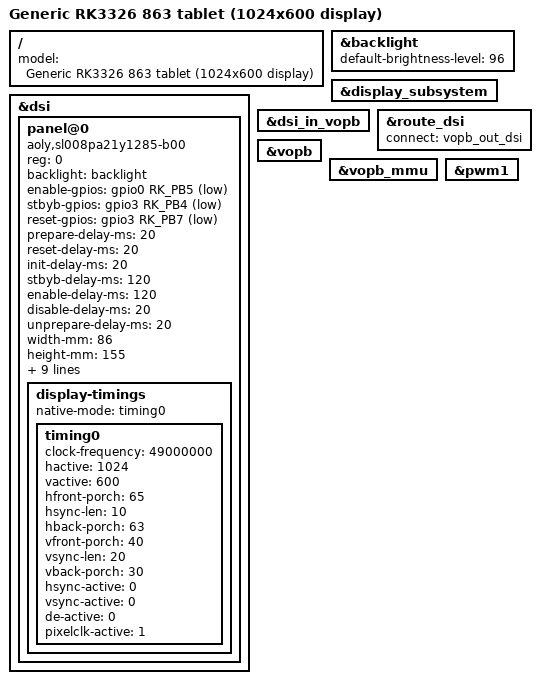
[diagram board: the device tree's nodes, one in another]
// SPDX-License-Identifier: (GPL-2.0+ OR MIT)

/dts-v1/;

#include <dt-bindings/display/drm_mipi_dsi.h>
#include "rk3326-863-tablet-common.dtsi"

/ {
	model = "Generic RK3326 863 tablet (1024x600 display)";
};

&backlight {
	default-brightness-level = <96>;
	status = "okay";
};

&display_subsystem {
	status = "okay";
};

&dsi {
	status = "okay";

	panel@0 {
		compatible = "aoly,sl008pa21y1285-b00",
			     "simple-panel-dsi";
		reg = <0>;
		status = "okay";
		backlight = <&backlight>;
		enable-gpios = <&gpio0 RK_PB5 GPIO_ACTIVE_LOW>;

		/*
		 * Preserved from the original DTB. Public Rockchip 6.1
		 * panel-simple does not currently consume this property.
		 */
		stbyb-gpios = <&gpio3 RK_PB4 GPIO_ACTIVE_LOW>;
		reset-gpios = <&gpio3 RK_PB7 GPIO_ACTIVE_LOW>;

		prepare-delay-ms = <20>;
		reset-delay-ms = <20>;
		init-delay-ms = <20>;
		stbyb-delay-ms = <120>;
		enable-delay-ms = <120>;
		disable-delay-ms = <20>;
		unprepare-delay-ms = <20>;

		width-mm = <86>;
		height-mm = <155>;

		dsi,flags = <(MIPI_DSI_MODE_VIDEO |
			      MIPI_DSI_MODE_VIDEO_BURST |
			      MIPI_DSI_MODE_LPM |
			      MIPI_DSI_MODE_NO_EOT_PACKET)>;
		dsi,format = <MIPI_DSI_FMT_RGB888>;
		dsi,lanes = <4>;
		bpc = <8>;

		panel-init-sequence = [
			05 78 01 11
			05 05 01 29
		];

		panel-exit-sequence = [
			05 00 01 28
			05 00 01 10
		];

		display-timings {
			native-mode = <&timing0>;

			timing0: timing0 {
				clock-frequency = <49000000>;
				hactive = <1024>;
				vactive = <600>;
				hfront-porch = <65>;
				hsync-len = <10>;
				hback-porch = <63>;
				vfront-porch = <40>;
				vsync-len = <20>;
				vback-porch = <30>;
				hsync-active = <0>;
				vsync-active = <0>;
				de-active = <0>;
				pixelclk-active = <1>;
			};
		};
	};
};

&dsi_in_vopb {
	status = "okay";
};

&route_dsi {
	connect = <&vopb_out_dsi>;
	status = "okay";
};

&vopb {
	status = "okay";
};

&vopb_mmu {
	status = "okay";
};

&pwm1 {
	status = "okay";
};
